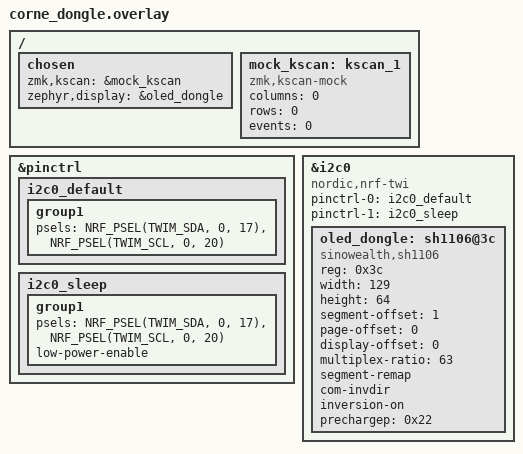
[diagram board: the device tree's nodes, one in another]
/*
* Copyright (c) 2021 Darryl deHaan
* SPDX-License-Identifier: MIT
*/

#include "corne.dtsi"

/{
    chosen {
        zmk,kscan = &mock_kscan;
        // Aponta para a label única que criamos abaixo
        zephyr,display = &oled_dongle;
    };

    mock_kscan: kscan_1 {
        compatible = "zmk,kscan-mock";
        columns = <0>;
        rows = <0>;
        events = <0>;
    };
};

&pinctrl {
    i2c0_default: i2c0_default {
        group1 {
            psels = <NRF_PSEL(TWIM_SDA, 0, 17)>,
                    <NRF_PSEL(TWIM_SCL, 0, 20)>;
        };
    };

    i2c0_sleep: i2c0_sleep {
        group1 {
            psels = <NRF_PSEL(TWIM_SDA, 0, 17)>,
                    <NRF_PSEL(TWIM_SCL, 0, 20)>;
            low-power-enable;
        };
    };    
}; 

&i2c0 {
    status = "okay";
    compatible = "nordic,nrf-twi";
    pinctrl-0 = <&i2c0_default>;
    pinctrl-1 = <&i2c0_sleep>;
    pinctrl-names = "default", "sleep";

    // Nome alterado para evitar conflito com o dtsi original
    oled_dongle: sh1106@3c {
        compatible = "sinowealth,sh1106";
        reg = <0x3c>;
        width = <129>;
        height = <64>;
        segment-offset = <1>;
        page-offset = <0>;
        display-offset = <0>;
        multiplex-ratio = <63>;
        segment-remap;
        com-invdir;
        inversion-on;
        prechargep = <0x22>;
    };
};
